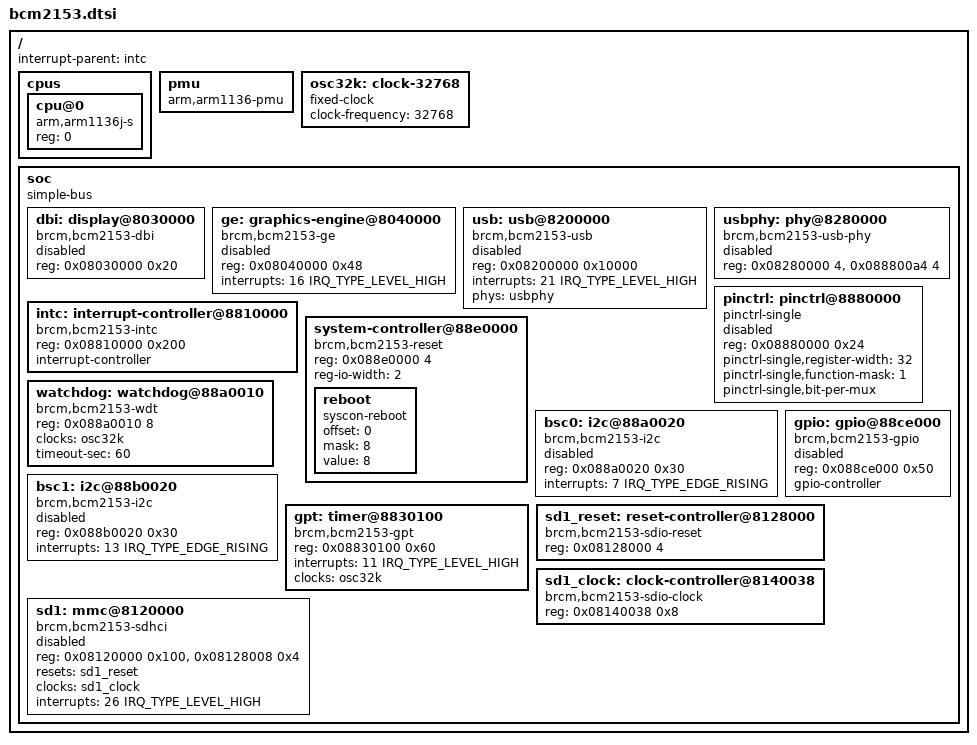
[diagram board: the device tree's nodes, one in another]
// SPDX-License-Identifier: (GPL-2.0-only OR BSD-2-Clause)

#include <dt-bindings/interrupt-controller/irq.h>

/ {
	#address-cells = <1>;
	#size-cells = <1>;
	interrupt-parent = <&intc>;

	cpus {
		#address-cells = <1>;
		#size-cells = <0>;

		cpu@0 {
			device_type = "cpu";
			compatible = "arm,arm1136j-s";
			reg = <0>;
		};
	};

	pmu {
		compatible = "arm,arm1136-pmu";
	};

	osc32k: clock-32768 {
		compatible = "fixed-clock";
		#clock-cells = <0>;
		clock-frequency = <32768>;
	};

	soc {
		compatible = "simple-bus";
		#address-cells = <1>;
		#size-cells = <1>;
		ranges;

		dbi: display@8030000 {
			compatible = "brcm,bcm2153-dbi";
			reg = <0x08030000 0x20>;
			status = "disabled";
		};

		ge: graphics-engine@8040000 {
			compatible = "brcm,bcm2153-ge";
			reg = <0x08040000 0x48>;
			interrupts = <16 IRQ_TYPE_LEVEL_HIGH>;
			status = "disabled";
		};

		usb: usb@8200000 {
			compatible = "brcm,bcm2153-usb", "snps,dwc2";
			reg = <0x08200000 0x10000>;
			interrupts = <21 IRQ_TYPE_LEVEL_HIGH>;
			phys = <&usbphy>;
			phy-names = "usb2-phy";
			status = "disabled";
		};

		usbphy: phy@8280000 {
			compatible = "brcm,bcm2153-usb-phy";
			reg = <0x08280000 4>, <0x088800a4 4>;
			reg-names = "wrapper", "analog";
			#phy-cells = <0>;
			status = "disabled";
		};

		pinctrl: pinctrl@8880000 {
			compatible = "pinctrl-single";
			reg = <0x08880000 0x24>;
			#pinctrl-cells = <2>;
			pinctrl-single,register-width = <32>;
			pinctrl-single,function-mask = <1>;
			pinctrl-single,bit-per-mux;
			status = "disabled";
		};

		intc: interrupt-controller@8810000 {
			compatible = "brcm,bcm2153-intc";
			reg = <0x08810000 0x200>;
			interrupt-controller;
			#address-cells = <0>;
			#interrupt-cells = <2>;
		};

		system-controller@88e0000 {
			compatible = "brcm,bcm2153-reset", "syscon", "simple-mfd";
			reg = <0x088e0000 4>;
			reg-io-width = <2>;

			reboot {
				compatible = "syscon-reboot";
				offset = <0>;
				mask = <8>;
				value = <8>;
			};
		};

		watchdog: watchdog@88a0010 {
			compatible = "brcm,bcm2153-wdt";
			reg = <0x088a0010 8>;
			clocks = <&osc32k>;
			clock-names = "slow";
			timeout-sec = <60>;
		};

		bsc0: i2c@88a0020 {
			compatible = "brcm,bcm2153-i2c";
			reg = <0x088a0020 0x30>;
			interrupts = <7 IRQ_TYPE_EDGE_RISING>;
			#address-cells = <1>;
			#size-cells = <0>;
			status = "disabled";
		};

		gpio: gpio@88ce000 {
			compatible = "brcm,bcm2153-gpio";
			reg = <0x088ce000 0x50>;
			gpio-controller;
			#gpio-cells = <2>;
			status = "disabled";
		};

		bsc1: i2c@88b0020 {
			compatible = "brcm,bcm2153-i2c";
			reg = <0x088b0020 0x30>;
			interrupts = <13 IRQ_TYPE_EDGE_RISING>;
			#address-cells = <1>;
			#size-cells = <0>;
			status = "disabled";
		};

		gpt: timer@8830100 {
			compatible = "brcm,bcm2153-gpt";
			reg = <0x08830100 0x60>;
			interrupts = <11 IRQ_TYPE_LEVEL_HIGH>;
			clocks = <&osc32k>;
			clock-names = "slow";
			status = "okay";
		};

		sd1_reset: reset-controller@8128000 {
			compatible = "brcm,bcm2153-sdio-reset";
			reg = <0x08128000 4>;
			#reset-cells = <0>;
		};

		sd1_clock: clock-controller@8140038 {
			compatible = "brcm,bcm2153-sdio-clock";
			reg = <0x08140038 0x8>;
			#clock-cells = <0>;
		};

		sd1: mmc@8120000 {
			compatible = "brcm,bcm2153-sdhci";
			reg = <0x08120000 0x100>,
			      <0x08128008 0x4>;
			reg-names = "host", "interrupt-mask";
			resets = <&sd1_reset>;
			clocks = <&sd1_clock>;
			interrupts = <26 IRQ_TYPE_LEVEL_HIGH>;
			status = "disabled";
		};
	};
};
